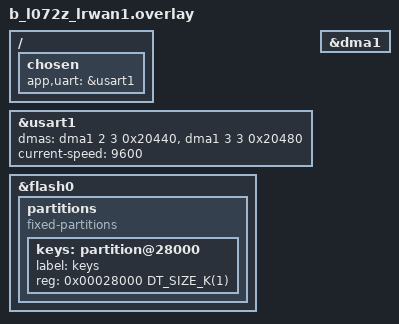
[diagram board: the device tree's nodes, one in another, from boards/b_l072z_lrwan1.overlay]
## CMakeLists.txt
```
# SPDX-License-Identifier: Apache-2.0

cmake_minimum_required(VERSION 3.20.0)

find_package(Zephyr REQUIRED HINTS $ENV{ZEPHYR_BASE})
project(smartmeter_send)

target_sources(app PRIVATE
	src/main.c
	src/uart.c
)

if (CONFIG_BT)
target_sources(app PRIVATE
	src/bluetooth.c
)
endif()

if (CONFIG_LORA)
target_sources(app PRIVATE
	src/lora.c
)
target_sources(loramac-node PRIVATE
    src/lorahack.c
)
endif()
```

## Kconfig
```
menu "Zephyr"
source "Kconfig.zephyr"
endmenu

menu "App"
config APP_UART_ASYNC_RX_BUFFER_SIZE
	int "Size in bytes of the RX buffers provided to UART driver"
	default 512
	help
	  Increasing this value decreases the number of UART interrupts needed
	  to receive large packets.

config APP_UART_ASYNC_RX_NUM_BUFFERS
	int "Number of RX buffers available to the UART driver"
	default 2
	help
	  This value needs to be at least 2 to avoid buffer starvation.

config APP_UART_ASYNC_RX_TIMEOUT_US
	int "Timeout for flushing RX buffers after receiving no additional data"
	default 3333
	help
	  Decreasing this value can help increase data throughput when high
	  baudrates are used. 3333us is 4 bytes at 9600 baud. Decreasing this
	  value too much can result in spurious interrupts. Leaving it too
	  high can reduce data throughput.

config APP_RINGBUF_SIZE
	int "Size of the RX ringbuffer"
	default 1024

config APP_SEND_INTERVAL
	int "lora send interval in seconds"
	default 60

config APP_SEND_TEST_EVENTS
	bool "send test events every 5s"
	help
	  This can be used to test without a connection to the power meter.
endmenu

module = APP
module-str = APP
source "subsys/logging/Kconfig.template.log_config"
```

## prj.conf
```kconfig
CONFIG_POLL=y
CONFIG_RING_BUFFER=y
CONFIG_UART_ASYNC_API=y
CONFIG_REBOOT=y
CONFIG_FLASH=y
CONFIG_FLASH_MAP=y
CONFIG_NVS=y
CONFIG_SETTINGS=y
CONFIG_SETTINGS_NVS=y

# for `pow`
CONFIG_PICOLIBC=y

CONFIG_NULL_POINTER_EXCEPTION_DETECTION_MPU=y
CONFIG_MPU_STACK_GUARD=y
CONFIG_STACK_SENTINEL=y

CONFIG_SMARTMETER_RUST=y
CONFIG_SYSTEM_WORKQUEUE_STACK_SIZE=2048

CONFIG_COMPILER_OPT="-Werror"
```

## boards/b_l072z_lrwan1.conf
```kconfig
CONFIG_SPI=y
CONFIG_GPIO=y
CONFIG_LORA=y
CONFIG_LORA_SX12XX=y
```

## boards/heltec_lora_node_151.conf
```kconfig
# stm32l1 doesn't have a hardware RNG, so use one based on the temperature sensor
# that not good, but better than nothing
CONFIG_SMARTMETER_TEMPRNG=y

# obtaining entropy using temprng is very slow, so use tinycrypt on top of it
CONFIG_CTR_DRBG_CSPRNG_GENERATOR=y
CONFIG_TINYCRYPT=y

CONFIG_SPI=y
CONFIG_GPIO=y
CONFIG_LORA=y
CONFIG_LORA_SX12XX=y
```

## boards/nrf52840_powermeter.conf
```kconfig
CONFIG_LOG=n
CONFIG_PRINTK=n
CONFIG_BOOT_BANNER=n

CONFIG_BT=y
CONFIG_BT_BROADCASTER=y
CONFIG_BT_EXT_ADV=y
CONFIG_BT_CTLR_PHY_CODED=y
CONFIG_BT_CTLR_ADV_DATA_LEN_MAX=64
CONFIG_BT_CTLR_TX_PWR_PLUS_8=y
```

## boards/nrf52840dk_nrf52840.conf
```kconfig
CONFIG_LOG=y
CONFIG_SMARTMETER_RUST_LOGGER=y
CONFIG_APP_LOG_LEVEL_DBG=y
CONFIG_SMARTMETER_DEBUG_PROFILE=y
CONFIG_MAIN_STACK_SIZE=8096
CONFIG_SYSTEM_WORKQUEUE_STACK_SIZE=8096

CONFIG_BT_DEBUG_LOG=y

CONFIG_BT=y
CONFIG_BT_BROADCASTER=y
CONFIG_BT_EXT_ADV=y
CONFIG_BT_CTLR_PHY_CODED=y
CONFIG_BT_CTLR_ADV_DATA_LEN_MAX=64
CONFIG_BT_CTLR_TX_PWR_PLUS_8=y
```

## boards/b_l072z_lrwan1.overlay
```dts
/ {
	chosen {
		app,uart = &usart1;
	};
};

&usart1 {
	dmas = <&dma1 2 3 0x20440>,
	       <&dma1 3 3 0x20480>;
	dma-names = "tx", "rx";
	current-speed = <9600>;
};

&dma1 {
	status = "okay";
};

&flash0 {
	partitions {
		compatible = "fixed-partitions";
		#address-cells = <1>;
		#size-cells = <1>;

		keys: partition@28000 {
			label = "keys";
			reg = <0x00028000 DT_SIZE_K(1)>;
		};
	};
};
```

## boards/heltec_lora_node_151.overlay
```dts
/ {
	chosen {
		app,uart = &usart2;
	};
};

&usart2 {
	dmas = <&dma1 6 0x20440>,
	       <&dma1 7 0x20480>;
	dma-names = "rx", "tx";
};


&dma1 {
	status = "okay";
};

&flash0 {
	partitions {
		compatible = "fixed-partitions";
		#address-cells = <1>;
		#size-cells = <1>;

		keys: partition@28000 {
			label = "keys";
			reg = <0x00028000 DT_SIZE_K(1)>;
		};
	};
};
```

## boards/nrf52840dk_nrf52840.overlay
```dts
/ {
	chosen {
		app,uart = &uart1;
	};
};

/delete-node/ &storage_partition;

&uart1 {
	current-speed = <9600>;
};

&flash0 {
	partitions {
		compatible = "fixed-partitions";
		#address-cells = <1>;
		#size-cells = <1>;

		keys: partition@f8000 {
			label = "keys";
			reg = <0x000f8000 DT_SIZE_K(1)>;
		};

		storage_partition: partition@f9000 {
			label = "storage";
			reg = <0x000f9000 0x00007000>;
		};
	};
};
```

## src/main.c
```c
#include <smartmeter-rust.h>
#include <zephyr/device.h>
#include <zephyr/storage/flash_map.h>
#include <zephyr/sys/reboot.h>

#include "main.h"

#include <zephyr/logging/log.h>
LOG_MODULE_REGISTER(main, CONFIG_APP_LOG_LEVEL);

#define DEFAULT_UART_NODE DT_CHOSEN(app_uart)
BUILD_ASSERT(DT_NODE_HAS_STATUS(DEFAULT_UART_NODE, okay), "No default UART specified in DT");

#ifdef CONFIG_LORA
#define DEFAULT_RADIO_NODE DT_ALIAS(lora0)
BUILD_ASSERT(DT_NODE_HAS_STATUS(DEFAULT_RADIO_NODE, okay), "No default LoRa radio specified in DT");
#endif

struct smr_cipher {
	uint8_t buf[32];
};

void app_unrecoverable_error(void)
{
	LOG_ERR("unrecoverable app error. wait a bit and reboot");
	k_sleep(K_MSEC(10000));
	LOG_ERR("Reboot now ...");
	sys_reboot(SYS_REBOOT_COLD);
}

#ifdef CONFIG_SMARTMETER_RUST_LOGGER
static uint32_t logger_sink(const enum smr_loglevel level, const void *const buf,
			    const uintptr_t len)
{
	static uint8_t logbuf[1000];
	static size_t logbuf_used = 0;
	static bool overflow = false;

	if (buf == NULL) {
		if (overflow) {
			LOG_WRN("**truncated**");
		} else {
			switch (level) {
			case smr_loglevel_error:
				LOG_ERR("%.*s", logbuf_used, logbuf);
				break;

			case smr_loglevel_warn:
				LOG_WRN("%.*s", logbuf_used, logbuf);
				break;

			case smr_loglevel_info:
				LOG_INF("%.*s", logbuf_used, logbuf);
				break;

			case smr_loglevel_debug:
				LOG_DBG("%.*s", logbuf_used, logbuf);
				break;

			case smr_loglevel_trace:
				LOG_DBG("TRACE - %.*s", logbuf_used, logbuf);
				break;

			default:
				break;
			}
		}

		overflow = false;
		logbuf_used = 0;
		return 0;
	}

	if (logbuf_used + len >= sizeof(logbuf)) {
		overflow = true;
		return 0;
	}

	memcpy(logbuf + logbuf_used, buf, len);
	logbuf_used += len;
	logbuf[logbuf_used] = 0;

	return 0;
}
#endif /* CONFIG_SMARTMETER_RUST_LOGGER */

#define KEYSIZE 32

static int read_key(uint8_t key[KEYSIZE])
{
	int ret;
	const struct flash_area *area;
	const size_t key_size = KEYSIZE;

	ret = flash_area_open(FIXED_PARTITION_ID(keys), &area);
	if (ret) {
		LOG_ERR("failed to open flash area: %d", ret);
		return ret;
	}

	if (area->fa_size < key_size) {
		LOG_ERR("partition has %zu bytes only", area->fa_size);
		ret = -1;
		goto err_close;
	}

	const uint32_t align = flash_area_align(area);
	if (key_size % align) {
		LOG_ERR("flash area needs unsupported alignment of %u bytes", (unsigned)align);
		ret = -1;
		goto err_close;
	}

	ret = flash_area_read(area, 0, key, key_size);
	if (ret) {
		LOG_ERR("failed to read key: %d", ret);
		goto err_close;
	}

	flash_area_close(area);
	return 0;

err_close:
	flash_area_close(area);
	return ret;
}

void app_uart_data_received(float active_energy, float active_power)
{
	ARG_UNUSED(active_energy);
	ARG_UNUSED(active_power);

#ifdef CONFIG_BT
	app_bluetooth_send_data(active_energy, active_power);
#endif
}

#ifdef CONFIG_APP_SEND_TEST_EVENTS
static struct k_work_delayable test_work;

static void test(struct k_work *work)
{
	LOG_INF("send test event");
	app_uart_data_received(1.0, 2.0);
	k_work_schedule(&test_work, K_SECONDS(5));
}
static K_WORK_DELAYABLE_DEFINE(test_work, test);
#endif

void main(void)
{
	static struct app_data data_ = { 0 };

	int ret;
	uint32_t smrrc;
	struct app_data *const data = &data_;

#ifdef CONFIG_SMARTMETER_RUST_LOGGER
	smrrc = smr_init_logger(logger_sink);
	if (smrrc) {
		LOG_ERR("sml logger init failed: %u", smrrc);
		app_unrecoverable_error();
		return;
	}
#endif

	// it's okay to store this on the stack because the cipher creates a copy
	uint8_t key[KEYSIZE];
	ret = read_key(key);
	if (ret) {
		LOG_ERR("failed to read key: %d", ret);
		app_unrecoverable_error();
		return;
	}

	LOG_INF("smr cipher size = %lu", smr_cipher_size());

	static struct smr_cipher cipher;
	smrrc = smr_cipher_create(&cipher, sizeof(cipher), key);
	if (smrrc) {
		LOG_ERR("can't create cipher: %u", smrrc);
		app_unrecoverable_error();
		return;
	}

#ifdef CONFIG_LORA
	ret = app_setup_lora(data, &cipher, DEVICE_DT_GET(DEFAULT_RADIO_NODE));
	if (ret) {
		LOG_ERR("failed to init LORA: %d", ret);
		app_unrecoverable_error();
		return;
	}
#endif

#ifdef CONFIG_BT
	ret = app_setup_bluetooth(data, &cipher);
	if (ret) {
		LOG_ERR("failed to init bluetooth: %d", ret);
		app_unrecoverable_error();
		return;
	}
#endif

	ret = app_setup_uart(data, DEVICE_DT_GET(DEFAULT_UART_NODE));
	if (ret) {
		LOG_ERR("failed to init UART: %d", ret);
		app_unrecoverable_error();
		return;
	}

#ifdef CONFIG_APP_SEND_TEST_EVENTS
	k_work_schedule(&test_work, K_SECONDS(5));
#endif
}
```

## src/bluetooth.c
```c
#include <stddef.h>
#include <zephyr/bluetooth/bluetooth.h>
#include <zephyr/bluetooth/hci.h>
#include <zephyr/settings/settings.h>
#include <zephyr/sys/printk.h>
#include <zephyr/sys/util.h>
#include <zephyr/types.h>

#include "main.h"

#include <zephyr/logging/log.h>
LOG_MODULE_REGISTER(main_bt, CONFIG_APP_LOG_LEVEL);

#define NONCE_SAVE_STEPS 1024

struct message {
	uint8_t nonce[12];
	float ciphertext[2];
	uint8_t tag[16];
} __packed;

struct mfg_data {
	uint8_t company_id[2];
	struct message message;
} __packed;

static const struct smr_cipher *g_cipher;
static struct bt_le_ext_adv *g_adv;
static struct smr_u128 g_nonce;
static float g_previous_active_power;
static float g_previous_active_energy;
static bool g_previous_valid = false;

static struct mfg_data mfg_data = {
	.company_id = { 0xff, 0xff },
};
BUILD_ASSERT(sizeof(mfg_data) == 38);

static const struct bt_data ad[] = {
	BT_DATA(BT_DATA_MANUFACTURER_DATA, &mfg_data, sizeof(mfg_data)),
};

static void disable_advertising(struct k_work *work)
{
	int ret = bt_le_ext_adv_stop(g_adv);
	if (ret) {
		LOG_ERR("Advertising failed to stop (delayed): %d", ret);
		return;
	}
}
static K_WORK_DELAYABLE_DEFINE(disable_advertising_work, disable_advertising);

void app_bluetooth_send_data(float active_energy, float active_power)
{
	int ret;

	LOG_INF("Sending advertising data");

	if (g_previous_valid && active_power == g_previous_active_power &&
	    active_energy == g_previous_active_energy) {
		LOG_DBG("ignore update that didn't change anything");
		return;
	}

	if (!g_adv) {
		LOG_ERR("incomplete bluetooth initialization");
		return;
	}

	if (smr_u128_inc(&g_nonce)) {
		LOG_ERR("can't increment nonce anymore");
		return;
	}

	if (!smr_u128_has_rem(&g_nonce, NONCE_SAVE_STEPS)) {
		ret = settings_save_one("app_bt/nonce", &g_nonce, sizeof(g_nonce));
		if (ret) {
			LOG_ERR("failed to save nonce: %d", ret);
			return;
		}
		LOG_HEXDUMP_INF(&g_nonce, sizeof(g_nonce), "saved nonce");
	}

	struct message message = {
		.ciphertext = {
			// TODO: convert endianess
			active_power,
			active_energy,
		},
	};

	if (smr_u128_to_nonce(message.nonce, sizeof(message.nonce), &g_nonce)) {
		LOG_ERR("nonce doesn't fit into u96 anymore");
		return;
	}

	ret = smr_encrypt(g_cipher, message.ciphertext, message.tag, message.nonce,
			  sizeof(message.ciphertext));
	if (ret) {
		LOG_ERR("failed to encrypt: %d", ret);
		return;
	}
	LOG_HEXDUMP_DBG(&message, sizeof(message), "ciphertext");

	mfg_data.message = message;

	ret = bt_le_ext_adv_set_data(g_adv, ad, ARRAY_SIZE(ad), NULL, 0);
	if (ret) {
		LOG_ERR("Failed to set advertising data for set: %d", ret);
		return;
	}

	ret = bt_le_ext_adv_start(g_adv, BT_LE_EXT_ADV_START_DEFAULT);
	if (ret && ret != -EALREADY) {
		LOG_ERR("Failed to start extended advertising set: %d", ret);
		return;
	}

	g_previous_active_power = active_power;
	g_previous_active_energy = active_energy;
	g_previous_valid = true;

	k_work_reschedule(&disable_advertising_work, K_SECONDS(2));
}

static int handle_set(const char *name, size_t len, settings_read_cb read_cb, void *cb_arg)
{
	const char *next;
	int rc;

	if (settings_name_steq(name, "nonce", &next) && !next) {
		struct smr_u128 new_nonce;

		if (len != sizeof(new_nonce)) {
			return -EINVAL;
		}

		rc = read_cb(cb_arg, &new_nonce, sizeof(new_nonce));
		if (rc < 0) {
			return rc;
		}

		LOG_HEXDUMP_INF(&new_nonce, sizeof(new_nonce), "loaded nonce");
		g_nonce = new_nonce;
		return 0;
	}

	return -ENOENT;
}

SETTINGS_STATIC_HANDLER_DEFINE(app_bt, "app_bt", NULL, handle_set, NULL, NULL);

int app_setup_bluetooth(struct app_data *data, const struct smr_cipher *cipher)
{
	int ret;

	g_cipher = cipher;

	ret = settings_subsys_init();
	if (ret) {
		LOG_ERR("failed to init settings subsys: %d", ret);
		return ret;
	}

	ret = settings_load();
	if (ret) {
		LOG_ERR("failed to load settings: %d", ret);
		return ret;
	}

	// skip the nonces we might hav already used but not saved
	if (smr_u128_add_u32(&g_nonce, NONCE_SAVE_STEPS)) {
		return -EINVAL;
	}

	ret = settings_save_one("app_bt/nonce", &g_nonce, sizeof(g_nonce));
	if (ret) {
		LOG_ERR("failed to save nonce: %d", ret);
		return ret;
	}

	LOG_INF("Starting Broadcaster");

	ret = bt_enable(NULL);
	if (ret) {
		LOG_ERR("Bluetooth init failed: %d", ret);
		return ret;
	}

	struct bt_le_adv_param adv_param = {
		.id = BT_ID_DEFAULT,
		.sid = 0U,
		.secondary_max_skip = 0U,
		.options = BT_LE_ADV_OPT_EXT_ADV | BT_LE_ADV_OPT_USE_IDENTITY | BT_LE_ADV_OPT_CODED,
		.interval_min = BT_GAP_ADV_SLOW_INT_MIN,
		.interval_max = BT_GAP_ADV_SLOW_INT_MAX,
		.peer = NULL,
	};
	ret = bt_le_ext_adv_create(&adv_param, NULL, &g_adv);
	if (ret) {
		LOG_ERR("Failed to create advertising set: %d", ret);
		return ret;
	}

	LOG_INF("Bluetooth initialized");

	return 0;
}
```

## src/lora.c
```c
#include <smartmeter-rust.h>
#include <zephyr/drivers/lora.h>
#include <zephyr/random/rand32.h>

#include "lorahack.h"
#include "main.h"

#include <zephyr/logging/log.h>
LOG_MODULE_REGISTER(main_lora, CONFIG_APP_LOG_LEVEL);

static const struct device *lora_dev;
static struct app_data *g_appdata;
static const struct smr_cipher *g_cipher;

static struct k_poll_signal lora_tx_signal = K_POLL_SIGNAL_INITIALIZER(lora_tx_signal);
static struct k_poll_event lora_tx_event =
	K_POLL_EVENT_INITIALIZER(K_POLL_TYPE_SIGNAL, K_POLL_MODE_NOTIFY_ONLY, &lora_tx_signal);
static struct k_work_poll lora_tx_work;

static bool lora_is_channel_free(const int16_t rssi_threshold, const uint32_t timeout_ms)
{
	const uint32_t timeout_cyc = k_ms_to_cyc_floor32(timeout_ms);
	bool ret = true;

	if (!lora_in_sleep_mode()) {
		// maybe a send is still in progess?
		return false;
	}

	lora_enter_receiver_mode();

	const uint32_t start_time = k_cycle_get_32();

	while (k_cycle_get_32() - start_time < timeout_cyc) {
		const int16_t rssi = lora_read_rssi();
		if (rssi > rssi_threshold) {
			ret = false;
			break;
		}
	}

	lora_enter_sleep_mode();

	return ret;
}

static void sender_work_handler(struct k_work *const work)
{
	struct k_work_delayable *const dwork = k_work_delayable_from_work(work);
	struct app_data *const data = g_appdata;
	const int64_t interval = CONFIG_APP_SEND_INTERVAL * 1000;
	int ret;
	k_timeout_t next_timeout;

	// check if we're allowed to send again
	const int64_t waited = k_uptime_get() - data->last_send;
	if (waited < interval) {
		const int64_t towait = interval - waited;
		LOG_DBG("duty-cycled. wait %lldms", (long long)towait);

		next_timeout = K_MSEC(towait);
		goto reschedule;
	}

	static struct {
		uint8_t nonce[12];
		float ciphertext[2];
		uint8_t tag[16];
	} message;
	BUILD_ASSERT(sizeof(message) == 36);
	memset(&message, 0, sizeof(message));

	ret = sys_csrand_get(message.nonce, sizeof(message.nonce));
	if (ret) {
		LOG_ERR("failed to generate nonce: %d", ret);

		next_timeout = K_MSEC(5000);
		goto reschedule;
	}

	// the encryption happens in place
	// NOTE: when `num_samples` is 0 this will result in NaN. That's useful
	//       so the receiver can see a difference between reachability and UART
	//       issues.
	// TODO: convert endianess
	message.ciphertext[0] = data->active_power / data->num_samples;
	message.ciphertext[1] = data->active_energy;

	ret = smr_encrypt(g_cipher, message.ciphertext, message.tag, message.nonce,
			  sizeof(message.ciphertext));
	if (ret) {
		LOG_ERR("failed to encrypt: %d", ret);

		next_timeout = K_MSEC(5000);
		goto reschedule;
	}

	LOG_HEXDUMP_DBG(&message, sizeof(message), "ciphertext");

	if (!lora_is_channel_free(-85, 1)) {
		LOG_WRN("channel is busy, don't send");

		next_timeout = K_MSEC(5000);
		goto reschedule;
	}

	data->last_send = k_uptime_get();
	data->active_power = 0;
	data->num_samples = 0;

	ret = k_work_poll_submit(&lora_tx_work, &lora_tx_event, 1, K_MSEC(10000));
	if (ret != 0) {
		LOG_ERR("Failed to submit uart rx work polling: %d", ret);
		app_unrecoverable_error();
		return;
	}

	ret = lora_send_async(lora_dev, (void *)&message, sizeof(message), &lora_tx_signal);
	if (ret < 0) {
		LOG_ERR("LoRa send failed: %d", ret);

		ret = k_work_poll_cancel(&lora_tx_work);
		if (ret) {
			LOG_WRN("can't cancel lora tx work: %d", ret);
		}

		next_timeout = K_MSEC(5000);
		goto reschedule;
	}

	// as soon as TX is done it'll schedule this work
	return;

reschedule:
	ret = k_work_schedule(dwork, next_timeout);
	if (ret < 0) {
		LOG_ERR("can't schedule work: %d", ret);
		app_unrecoverable_error();
	}
}
static K_WORK_DELAYABLE_DEFINE(sender_work, sender_work_handler);

static void lora_tx_work_handler(struct k_work *work)
{
	LOG_INF("successfully sent data");

	const int ret = k_work_schedule(&sender_work, K_NO_WAIT);
	if (ret < 0) {
		LOG_ERR("can't schedule work: %d", ret);
		app_unrecoverable_error();
	}
}

int app_setup_lora(struct app_data *const data, const struct smr_cipher *const cipher,
		   const struct device *const dev)
{
	if (!device_is_ready(dev)) {
		LOG_ERR("%s Device not ready", dev->name);
		return -EAGAIN;
	}
	lora_dev = dev;
	g_appdata = data;
	g_cipher = cipher;

	struct lora_modem_config config = {
		.frequency = 868300000,
		.bandwidth = BW_250_KHZ,
		.datarate = SF_7,
		.preamble_len = 8,
		.coding_rate = CR_4_5,
		.tx_power = -2,
		.tx = true,
	};
	int ret = lora_config(lora_dev, &config);
	if (ret < 0) {
		LOG_ERR("LoRa config failed: %d", ret);
		return ret;
	}

	// this prevents sending excessively in case of reset loops
	data->last_send = k_uptime_get();

	k_work_poll_init(&lora_tx_work, lora_tx_work_handler);

	ret = k_work_schedule(&sender_work, K_NO_WAIT);
	if (ret < 0) {
		LOG_ERR("can't schedule work: %d", ret);
		return ret;
	}

	return 0;
}
```

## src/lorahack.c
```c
/// @file
/// implements code that requires headers and compile-time options that are not
/// available in the public API exposed by Zephyr
///
/// This compilation unit is added into the `loramac-node` library.
#include "lorahack.h"

#include <sx1276-board.h>
#include <sx1276/sx1276.h>

void lora_enter_receiver_mode(void)
{
	uint8_t opMode = RF_OPMODE_RECEIVER;

	// Enable TCXO if operating mode different from SLEEP.
	SX1276SetBoardTcxo(true);
	SX1276SetAntSwLowPower(false);
	SX1276SetAntSw(opMode);
	SX1276Write(REG_OPMODE, (SX1276Read(REG_OPMODE) & RF_OPMODE_MASK) | opMode);
}

void lora_enter_sleep_mode(void)
{
	SX1276SetSleep();
}

bool lora_in_sleep_mode(void)
{
	return SX1276GetStatus() == RF_OPMODE_SLEEP;
}

int16_t lora_read_rssi(void)
{
	return SX1276ReadRssi(MODEM_LORA);
}
```

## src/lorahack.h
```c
#ifndef LORA_HACK_H
#define LORA_HACK_H

#include <stdbool.h>
#include <stdint.h>

void lora_enter_receiver_mode(void);
void lora_enter_sleep_mode(void);
bool lora_in_sleep_mode(void);
int16_t lora_read_rssi(void);

#endif /* LORA_HACK_H */
```

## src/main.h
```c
#ifndef MAIN_H
#define MAIN_H

#include <smartmeter-rust.h>
#include <stdint.h>
#include <zephyr/device.h>

struct app_data {
	float active_energy;
	float active_power;
	size_t num_samples;
	int64_t last_send;
};

void app_unrecoverable_error(void);
#ifdef CONFIG_BT
int app_setup_bluetooth(struct app_data *data, const struct smr_cipher *cipher);
void app_bluetooth_send_data(float active_energy, float active_power);
#endif
#ifdef CONFIG_LORA
int app_setup_lora(struct app_data *data, const struct smr_cipher *cipher,
		   const struct device *dev);
#endif
int app_setup_uart(struct app_data *data, const struct device *dev);

void app_uart_data_received(float active_energy, float active_power);

#endif /* MAIN_H */
```

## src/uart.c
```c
#include <math.h>
#include <smartmeter-rust.h>
#include <zephyr/drivers/uart.h>
#include <zephyr/sys/ring_buffer.h>

#include "main.h"

#include <zephyr/logging/log.h>
LOG_MODULE_REGISTER(main_uart, CONFIG_APP_LOG_LEVEL);

struct smr_context {
	uint8_t buf[520];
};

#define RX_BUFFER_SIZE CONFIG_APP_UART_ASYNC_RX_BUFFER_SIZE
#define RX_BUFFER_NUM CONFIG_APP_UART_ASYNC_RX_NUM_BUFFERS
static K_MEM_SLAB_DEFINE(uart_async_rx_slab, RX_BUFFER_SIZE, RX_BUFFER_NUM, 1);

static K_SEM_DEFINE(uart_rx_sem, 0, 1);
static struct k_poll_event uart_rx_event = K_POLL_EVENT_STATIC_INITIALIZER(
	K_POLL_TYPE_SEM_AVAILABLE, K_POLL_MODE_NOTIFY_ONLY, &uart_rx_sem, 0);
static struct k_work_poll uart_rx_work;

// NOTE: `RING_BUF_DECLARE` doesn't support static linkage
static uint8_t rx_rb_buf[CONFIG_APP_RINGBUF_SIZE];
static struct ring_buf rx_rb;

static void uart_async_callback(const struct device *const dev, struct uart_event *const evt,
				void *const data)
{
	uint32_t written;
	void *buf;
	int rc;

	ARG_UNUSED(data);

	switch (evt->type) {
	case UART_RX_BUF_REQUEST:
		/* Allocate next RX buffer for UART driver */
		rc = k_mem_slab_alloc(&uart_async_rx_slab, (void **)&buf, K_NO_WAIT);
		if (rc < 0) {
			/* Major problems, UART_RX_BUF_RELEASED event is not being generated, or
			 * CONFIG_MODEM_IFACE_UART_ASYNC_RX_NUM_BUFFERS is not large enough.
			 */
			LOG_ERR("RX buffer starvation");
			break;
		}
		/* Provide the buffer to the UART driver */
		uart_rx_buf_rsp(dev, buf, RX_BUFFER_SIZE);
		break;
	case UART_RX_BUF_RELEASED:
		/* UART driver is done with memory, free it */
		k_mem_slab_free(&uart_async_rx_slab, (void **)&evt->data.rx_buf.buf);
		break;
	case UART_RX_RDY:
		/* Place received data on the ring buffer */
		written = ring_buf_put(&rx_rb, evt->data.rx.buf + evt->data.rx.offset,
				       evt->data.rx.len);
		if (written != evt->data.rx.len) {
			LOG_WRN("Received bytes dropped from ring buf");
		}
		/* Notify upper layer that new data has arrived */
		k_sem_give(&uart_rx_sem);
		break;
	default:
		break;
	}
}

static struct smr_context __aligned(8) smlctx;
static void uart_rx_work_handler(struct k_work *work)
{
	int ret;
	uint32_t smlrc;

	ARG_UNUSED(work);

	if (k_sem_take(&uart_rx_sem, K_NO_WAIT) != 0) {
		// if it's NULL, it's the initial call from the main function
		if (work) {
			LOG_WRN("spurious uart work handler call");
		}
		goto resubmit;
	}

	smlrc = sml_poll(&smlctx);
	if (smlrc) {
		LOG_ERR("sml poll failed: %u", smlrc);
		app_unrecoverable_error();
		return;
	}

resubmit:
	ret = k_work_poll_submit(&uart_rx_work, &uart_rx_event, 1, K_FOREVER);
	if (ret != 0) {
		LOG_ERR("Failed to submit uart rx work polling: %d", ret);
		app_unrecoverable_error();
		return;
	}
}

static uint32_t sml_read_cb(void *const buf, const uintptr_t max_length,
			    uintptr_t *const out_length)
{
	const uint32_t bytes_read = ring_buf_get(&rx_rb, buf, max_length);
	*out_length = bytes_read;
	return 0;
}

static void sml_data_cb(void *const data_, const struct smr_callback_data *const cbdata)
{
	struct app_data *const data = data_;

	const float active_power =
		cbdata->active_power.value * pow(10.0, cbdata->active_power.scaler);
	const float active_energy =
		cbdata->active_energy.value * pow(10.0, cbdata->active_energy.scaler);

	// sum the data for average calculation
	data->active_power += active_power;
	data->num_samples++;

	data->active_energy = active_energy;

	LOG_DBG("got data: active_power=%llu*10^%d active_energy=%llu*10^%d",
		(unsigned long long)cbdata->active_power.value, (int)cbdata->active_power.scaler,
		(unsigned long long)cbdata->active_energy.value, (int)cbdata->active_energy.scaler);
	LOG_INF("power:%llu energy:%llu",
		(unsigned long long)(data->active_power / data->num_samples),
		(unsigned long long)data->active_energy);

	app_uart_data_received(active_energy, active_power);
}

int app_setup_uart(struct app_data *const data, const struct device *const dev)
{
	int ret;
	void *buf;

	if (!device_is_ready(dev)) {
		LOG_ERR("%s Device not ready", dev->name);
		return -EAGAIN;
	}

	ring_buf_init(&rx_rb, sizeof(rx_rb_buf), rx_rb_buf);

	/* Configure async UART callback */
	ret = uart_callback_set(dev, uart_async_callback, data);
	if (ret < 0) {
		LOG_ERR("Failed to set UART callback");
		return ret;
	}

	/* Enable reception permanently on the interface */
	k_mem_slab_alloc(&uart_async_rx_slab, (void **)&buf, K_FOREVER);
	ret = uart_rx_enable(dev, buf, RX_BUFFER_SIZE, CONFIG_APP_UART_ASYNC_RX_TIMEOUT_US);
	if (ret < 0) {
		LOG_ERR("Failed to enable UART RX");
		return ret;
	}

	LOG_INF("sml ctxsz = %lu", sml_ctxsz());

	const uint32_t smlrc = sml_init(&smlctx, sizeof(smlctx), data, sml_read_cb, sml_data_cb);
	if (smlrc) {
		LOG_ERR("sml init failed: %u", smlrc);
		return -1;
	}
	k_work_poll_init(&uart_rx_work, uart_rx_work_handler);
	uart_rx_work_handler(NULL);

	return 0;
}
```
